# V3s register map
Vendor: Allwinner; Series: V3s; File version: 0.1
CPU: ARM Cortex-A7 MP1 0, little endian, MPU, no FPU, 0 interrupt priority bits
Registers are 32-bit, read-write, reset 0x0 unless marked. A register's access mark holds for its fields unless they carry their own. Offsets are from the block's base; [hi:lo] are bit positions; 'fields as' and 'values as' point back to an identical list.

## PWM
Base 0x01C21400
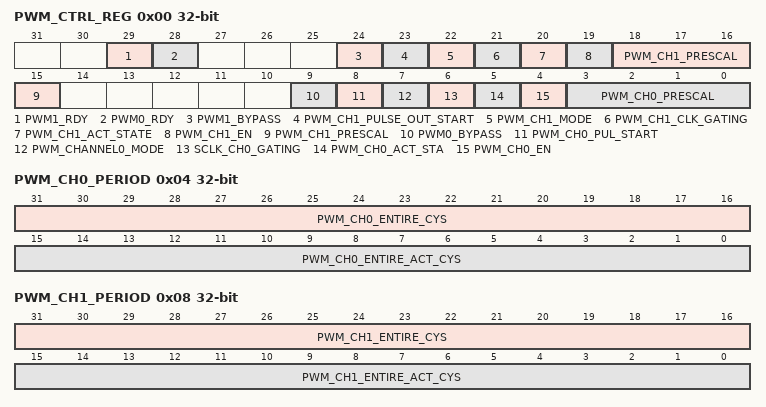
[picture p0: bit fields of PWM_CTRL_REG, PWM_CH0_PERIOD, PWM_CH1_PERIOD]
0x00 PWM_CTRL_REG
  [29] PWM1_RDY ro — PWM1 period register ready. 0: PWM1 period register is ready to write, 1: PWM1 period register is busy.
    0=ready (PWM1 period register is ready to write,); 1=busy (PWM1 period register is busy.)
  [28] PWM0_RDY ro — PWM0 period register ready. 0: PWM0 period register is ready to write, 1: PWM0 period register is busy.
    0=ready (PWM0 period register is ready to write,); 1=busy (PWM0 period register is busy.)
  [24] PWM1_BYPASS — PWM CH1 bypass enable. If the bit is set to 1, PWM1`s output is OSC24MHz. 0: disable 1: enable
    0=disable; 1=enable
  [23] PWM_CH1_PULSE_OUT_START — PWM Channel 1 pulse output start. 0: no effect, 1: output 1 pulse. The pulse width should be according to the period 1 register[15:0],and the pulse state should be according to the active state. After the pulse is finished, the bit will be cleared automatically.
    0=no_effect; 1=output 1 pulse. The pulse width should be according to the period 1 register[15:0],and the pulse state should be according to the active state. After the pulse is finished, the bit will be cleared automatically.
  [22] PWM_CH1_MODE — PWM Channel 1 mode. 0: cycle mode, 1: pulse mode.
    0=cycle mode,; 1=pulse mode
  [21] PWM_CH1_CLK_GATING — Gating the Special Clock for PWM1(0: mask, 1: pass).
  [20] PWM_CH1_ACT_STATE — PWM Channel 1 Active State. 0: Low Level, 1: High Level.
    0=Low (Low Level,); 1=High Level
  [19] PWM_CH1_EN — PWM Channel 1 Enable. 0: Disable, 1: Enable.
    0=Disable; 1=Enable
  [18:15] PWM_CH1_PRESCAL — PWM Channel 1 Prescalar. These bits should be setting before the PWM Channel 1 clock gate on. 0000: /120 0001: /180 0010: /240 0011: /360 0100: /480 0101: / 0110: / 0111: / 1000: /12k 1001: /24k 1010: /36k 1011: /48k 1100: /72k 1101: / 1110: / 1111: /1
    0=_slash_120 (/120); 1=_slash_180 (/180); 2=_slash_240 (/240); 3=_slash_360 (/360); 4=_slash_480 (/480); 8=_slash_12k (/12k); 9=_slash_24k (/24k); 10=_slash_36k (/36k); 11=_slash_48k (/48k); 12=_slash_72k (/72k); 15=_slash_1 (/1)
  [9] PWM0_BYPASS — PWM CH0 bypass enable. If the bit is set to 1, PWM0`s output is OSC24MHz. 0: disable, 1: enable.
    0=disable; 1=enable
  [8] PWM_CH0_PUL_START — PWM Channel 0 pulse output start. 0: no effect, 1: output 1 pulse. The pulse width should be according to the period 0 register[15:0],and the pulse state should be according to the active state. After the pulse is finished,the bit will be cleared automatically.
    0=no_effect; 1=output 1 pulse. The pulse width should be according to the period 0 register[15:0],and the pulse state should be according to the active state. After the pulse is finished,the bit will be cleared automatically.
  [7] PWM_CHANNEL0_MODE — 0: cycle mode, 1: pulse mode.
    0=cycle mode,; 1=pulse mode
  [6] SCLK_CH0_GATING — Gating the Special Clock for PWM0(0: mask, 1: pass).
  [5] PWM_CH0_ACT_STA — PWM Channel 0 Active State. 0: Low Level, 1: High Level.
    0=Low (Low Level,); 1=High Level
  [4] PWM_CH0_EN — PWM Channel 0 Enable. 0: Disable, 1: Enable.
    0=Disable; 1=Enable
  [3:0] PWM_CH0_PRESCAL — PWM Channel 0 Prescalar. These bits should be setting before the PWM Channel 0 clock gate on. 0000: /120 0001: /180 0010: /240 0011: /360 0100: /480 0101: / 0110: / 0111: / 1000: /12k 1001: /24k 1010: /36k 1011: /48k 1100: /72k 1101: / 1110: / 1111: /1
    values as PWM_CH1_PRESCAL
0x04 PWM_CH0_PERIOD reset not defined — PWM Channel 0 Period Register
  [31:16] PWM_CH0_ENTIRE_CYS — Number of the entire cycles in the PWM clock. 0 = 1 cycle 1 = 2 cycles ... N = N+1 cycles If the register need to be modified dynamically, the PCLK should be faster than the PWM CLK (PWM CLK = 24MHz/pre-scale).
  [15:0] PWM_CH0_ENTIRE_ACT_CYS — Number of the active cycles in the PWM clock. 0 = 0 cycle 1 = 1 cycles ... N = N cycles
0x08 PWM_CH1_PERIOD reset not defined — PWM Channel 1 Period Register
  [31:16] PWM_CH1_ENTIRE_CYS — Number of the entire cycles in the PWM clock. 0 = 1 cycle 1 = 2 cycles ... N = N+1 cycles If the register need to be modified dynamically, the PCLK should be faster than the PWM CLK (PWM CLK = 24MHz/pre-scale).
  [15:0] PWM_CH1_ENTIRE_ACT_CYS — Number of the active cycles in the PWM clock. 0 = 0 cycle 1 = 1 cycles ... N = N cycles
